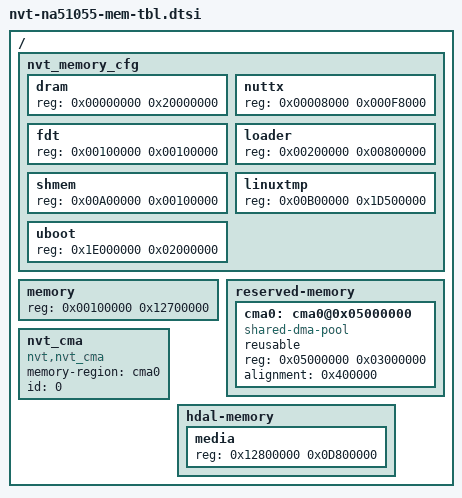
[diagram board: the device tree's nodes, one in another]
/*
 * Novatek Ltd. NA51055 BSP part of dts
 *
 * Cortex-A9
 *
 */
/ {
	/* Uboot/loader memory layout */
	nvt_memory_cfg {
		#address-cells = <1>;
		#size-cells = <1>;
		dram {	        reg = <0x00000000 0x20000000>;	};
		nuttx{          reg = <0x00008000 0x000F8000>;  };
		fdt {           reg = <0x00100000 0x00100000>;	};
		loader {        reg = <0x00200000 0x00800000>;	};
		shmem{	        reg = <0x00A00000 0x00100000>;	};
		linuxtmp{	reg = <0x00B00000 0x1D500000>;	};
		uboot{	        reg = <0x1E000000 0x02000000>;	};
	};

	/* Linux system memory region*/
	memory { device_type = "memory"; reg = <0x00100000 0x12700000>; };

	/* Linux setup reserved memory */
	reserved-memory {
		#address-cells = <1>;
		#size-cells = <1>;
		ranges;

		cma0: cma0@0x05000000 {
			compatible = "shared-dma-pool";
			reusable;
			reg = <0x05000000 0x03000000>;
			alignment = <0x400000>;
			status = "okay";
		};
	};

	nvt_cma {
		compatible = "nvt,nvt_cma";
		memory-region = <&cma0>;
		id = <0>;
	};

	hdal-memory {
		#address-cells = <1>;
		#size-cells = <1>;
		media { reg = <0x12800000 0x0D800000>; };
	};
};
